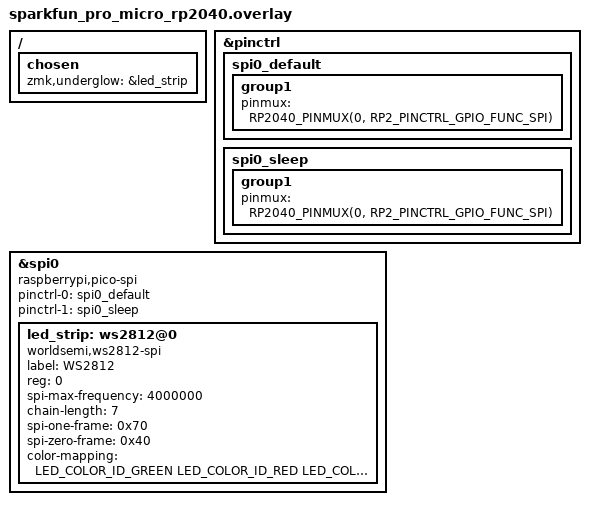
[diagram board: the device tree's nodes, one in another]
#include <dt-bindings/pinctrl/rpi-pico-rp2040-pinctrl.h>
#include <dt-bindings/led/led.h>

&pinctrl {
    spi0_default: spi0_default {
        group1 {
            pinmux = <RP2040_PINMUX(0, RP2_PINCTRL_GPIO_FUNC_SPI)>;
        };
    };

    spi0_sleep: spi0_sleep {
        group1 {
            pinmux = <RP2040_PINMUX(0, RP2_PINCTRL_GPIO_FUNC_SPI)>;
        };
    };
};

&spi0 {
    compatible = "raspberrypi,pico-spi", "arm,pl022";
    status = "okay";

    pinctrl-0 = <&spi0_default>;
    pinctrl-1 = <&spi0_sleep>;
    pinctrl-names = "default", "sleep";

    led_strip: ws2812@0 {
        compatible = "worldsemi,ws2812-spi";
        label = "WS2812";

        /* SPI */
        reg = <0>; /* ignored, but necessary for SPI bindings */
        spi-max-frequency = <4000000>;

        /* WS2812 */
        chain-length = <7>;
        spi-one-frame = <0x70>;
        spi-zero-frame = <0x40>;

        color-mapping = <LED_COLOR_ID_GREEN LED_COLOR_ID_RED LED_COLOR_ID_BLUE>;
    };
};

/ {
    chosen {
        zmk,underglow = &led_strip;
    };
};
